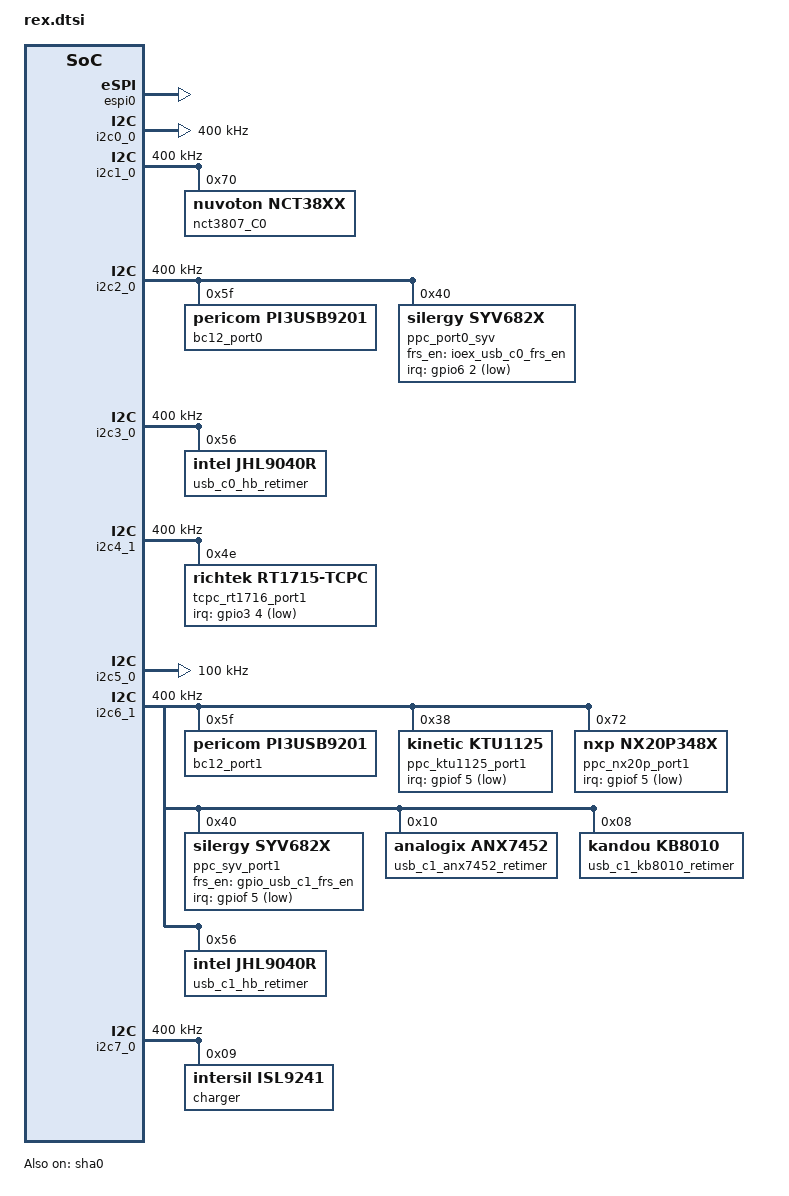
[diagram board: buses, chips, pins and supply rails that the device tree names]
/* Copyright 2022 The ChromiumOS Authors
 * Use of this source code is governed by a BSD-style license that can be
 * found in the LICENSE file.
 */

#include <dt-bindings/usb_pd_tcpm.h>
#include <cros/integrated_fwid.dtsi>

/ {
	aliases {
		gpio-wp = &gpio_ec_wp_l;
		gpio-cbi-wp = &gpio_ec_cbi_wp;
		gpio-kbd-kso2 = &gpio_ec_kso_02_inv;
	};

	named-gpios {
		compatible = "named-gpios";

		gpio_ec_entering_rw: ec_entering_rw {
			enum-name = "GPIO_ENTERING_RW";
		};

		ioex_usb_c0_sbu_fault_odl: usb_c0_sbu_fault_odl {
			gpios = <&ioex_c0_port1 2 GPIO_INPUT>;
		};
		ioex_usb_c0_rt_rst_ls_l: usb_c0_rt_rst_ls_l {
			gpios = <&ioex_c0_port0 7 GPIO_OUTPUT>;
		};

		ioex_usb_c0_frs_en: usb_c0_frs_en {
			gpios = <&ioex_c0_port0 6 GPIO_OUTPUT_LOW>;
		};

		/* Need to designate 1.8V for I2C buses on the 1800mV rail */
		ec-i2c-sensor-scl {
			gpios = <&gpiob 5 (GPIO_INPUT | GPIO_VOLTAGE_1P8)>;
		};
		ec-i2c-sensor-sda {
			gpios = <&gpiob 4 (GPIO_INPUT | GPIO_VOLTAGE_1P8)>;
		};
		ec-i2c-c0-rt-scl {
			gpios = <&gpiod 1 (GPIO_INPUT | GPIO_VOLTAGE_1P8)>;
		};
		ec-i2c-c0-rt-sda {
			gpios = <&gpiod 0 (GPIO_INPUT | GPIO_VOLTAGE_1P8)>;
		};

		/* Overrides for generated.dtsi */
		ec_edp_bl_en {
			gpios = <&gpiod 3 GPIO_OUTPUT_LOW>;
		};
		en_pp5000_fan {
			gpios = <&gpio6 1 GPIO_OUTPUT_LOW>;
		};
		usb_c0_tcpc_rst_odl {
			gpios = <&gpio6 7 (GPIO_ODR_HIGH | GPIO_ACTIVE_LOW)>;
		};
		usb_c0_ppc_int_odl {
			gpios = <&gpio6 2 (GPIO_INPUT | GPIO_ACTIVE_LOW)>;
		};
		usb_c1_ppc_int_odl {
			gpios = <&gpiof 5 (GPIO_INPUT | GPIO_ACTIVE_LOW)>;
		};
	};

	named-gpios {
		compatible = "named-gpios";

		/*
		 * Override auto-generated GPIO definitions for pins
		 * that are reconfigured at runtime for specific
		 * daughterboards.
		 *
		 * The flags parameter needs to be 0 here because
		 * gpio_pin_configure_dt() can only add flags.
		 */

		usb_c1_rst_odl {
			gpios = <&gpio3 7 0>;
			no-auto-init;
		};
		usb_c1_rt_int_odl {
			gpios = <&gpio7 2 0>;
			no-auto-init;
		};
		usb_c1_rt_rst_r_odl {
			gpios = <&gpio7 4 0>;
			no-auto-init;
		};
		usb_c1_frs_en {
			gpios = <&gpio8 3 0>;
			no-auto-init;
		};
	};

	aliases {
		/* GPIO37 */
		kb-usb-c1-rst-odl = &gpio_usb_c1_rst_odl;
		anx-usb-c1-rt-hpd-in = &gpio_usb_c1_rst_odl;
		hb-usb-c1-rst-odl = &gpio_usb_c1_rst_odl;

		/* GPIO72 */
		kb-usb-c1-dp-mode = &gpio_usb_c1_rt_int_odl;
		anx-usb-c1-rt-dp-en = &gpio_usb_c1_rt_int_odl;
		hb-usb-c1-int-odl = &gpio_usb_c1_rt_int_odl;

		/* GPIO74 */
		ps-usb-c1-rt-rst-odl = &gpio_usb_c1_rt_rst_r_odl;
		kb-usb-c1-rt-rst-odl = &gpio_usb_c1_rt_rst_r_odl;
		anx-usb-c1-rt-usb-en = &gpio_usb_c1_rt_rst_r_odl;
		hb-usb-c1-rt-rst-odl = &gpio_usb_c1_rt_rst_r_odl;

		/* GPIO83 */
		kb-usb-c1-frs-alert = &gpio_usb_c1_frs_en;
		anx-usb-c1-frs-en = &gpio_usb_c1_frs_en;
		hb-usb-c1-frs-en = &gpio_usb_c1_frs_en;
	};

	/* Special I2C port attribute */
	named-i2c-ports {
		ec_i2c_usb_c1_tcp {
			dynamic-speed;
		};
	};

	usba-port-enable-list {
		compatible = "cros-ec,usba-port-enable-pins";
		enable-pins = <&gpio_en_pp5000_usba_r>;
	};
};

/* host interface */
&espi0 {
	status = "okay";
	pinctrl-0 = <&espi_lpc_gp46_47_51_52_53_54_55_57>;
	pinctrl-names = "default";
};

&sha0 {
	status = "okay";
};

/* Power switch logic input pads */
&psl_in1_gpd2 {
	/* LID_OPEN */
	psl-in-mode = "edge";
	psl-in-pol = "high-rising";
};

&psl_in2_gp00 {
	/* ACOK_OD */
	psl-in-mode = "edge";
	psl-in-pol = "high-rising";
};

&psl_in4_gp02 {
	/* MECH_PWR_BTN_ODL */
	psl-in-mode = "edge";
	psl-in-pol = "low-falling";
};

/* Power domain device controlled by PSL (Power Switch Logic) IO pads */
&power_ctrl_psl {
	status = "okay";
	pinctrl-names = "sleep";
	pinctrl-0 = <&psl_in1_gpd2 &psl_in2_gp00 &psl_in4_gp02>;
};

&i2c0_0 {
	label = "I2C_SENSOR";
	clock-frequency = <I2C_BITRATE_FAST>;
};

&i2c1_0 {
	label = "I2C_USB_C0_TCPC";
	clock-frequency = <I2C_BITRATE_FAST>;

	nct3807_C0: nct38xx@70 {
		compatible = "nuvoton,nct38xx";
		reg = <0x70>;

		tcpc_port0: nct38xx-tcpc {
			compatible = "nuvoton,nct38xx-tcpc";
			gpio-dev = <&nct38xx_gpio_C0>;
			tcpc-flags = <(
				TCPC_FLAGS_TCPCI_REV2_0 |
				TCPC_FLAGS_TCPCI_REV2_0_NO_VSAFE0V)>;
			/* a duplicate of the <&gpio_usb_c0_tcpc_int_odl> node
			 * in "named-gpios". This is the Zephyr preferred style,
			 * the "named-gpios" node will be dealt with at a later
			 * date.
			 */
			irq-gpios = <&gpioe 0 GPIO_ACTIVE_LOW>;
			/* a duplicate of the <&gpio_usb_c0_tcpc_rst_odl> node
			 * in "named-gpios". This is the Zephyr preferred style,
			 * the "named-gpios" node will be dealt with at a later
			 * date.
			 */
			rst-gpios = <&gpio6 7
				     (GPIO_OPEN_DRAIN | GPIO_ACTIVE_LOW)>;
		};

		nct38xx_gpio_C0: nct38xx-gpio {
			#address-cells = <1>;
			#size-cells = <0>;
			compatible = "nuvoton,nct38xx-gpio";
			label = "NCT3807_C0";

			ioex_c0_port0: gpio@0 {
				compatible = "nuvoton,nct38xx-gpio-port";
				reg = <0x0>;
				label = "NCT3807_C0_GPIO0";
				gpio-controller;
				#gpio-cells = <2>;
				ngpios = <8>;
				pin_mask = <0xff>;
				pinmux_mask = <0xf7>;
			};
			ioex_c0_port1: gpio@1 {
				compatible = "nuvoton,nct38xx-gpio-port";
				reg = <0x1>;
				label = "NCT3807_C0_GPIO1";
				gpio-controller;
				#gpio-cells = <2>;
				ngpios = <8>;
				pin_mask = <0xff>;
			};
		};
	};
};

&i2c2_0 {
	label = "I2C_PPC0";
	clock-frequency = <I2C_BITRATE_FAST>;

	bc12_port0: pi3usb9201@5f {
		compatible = "pericom,pi3usb9201";
		status = "okay";
		reg = <0x5f>;
		irq = <&int_usb_c0_bc12>;
	};

	ppc_port0_syv: ppc_syv@40 {
		compatible = "silergy,syv682x";
		status = "okay";
		reg = <0x40>;
		frs_en_gpio = <&ioex_usb_c0_frs_en>;
		/* a duplicate of the <&gpio_usb_c0_ppc_int_odl> node in
		 * "named-gpios". This is the Zephyr preferred style,
		 * the "named-gpios" node will be dealt with at a later date.
		 */
		irq-gpios = <&gpio6 2 GPIO_ACTIVE_LOW>;
	};
};

&i2c3_0 {
	label = "I2C_USB_C0_RT";
	clock-frequency = <I2C_BITRATE_FAST>;

	usb_c0_hb_retimer: jhl9040r-c0@56 {
		compatible = "intel,jhl9040r";
		reg = <0x56>;
		ls-en-pin = <&gpio_usb_c0_rt_3p3_sx_en>;
		int-pin = <&gpio_usb_c0_rt_int_odl>;
		reset-pin = <&ioex_usb_c0_rt_rst_ls_l>;
	};
};

&i2c4_1 {
	label = "I2C_USB_C1_TCPC";
	clock-frequency = <I2C_BITRATE_FAST>;

	tcpc_rt1716_port1: rt1716@4e {
		compatible = "richtek,rt1715-tcpc";
		reg = <0x4e>;
		tcpc-flags = <(TCPC_FLAGS_TCPCI_REV2_0 |
			TCPC_FLAGS_TCPCI_REV2_0_NO_VSAFE0V)>;
		/* a duplicate of the <&gpio_usb_c1_tcpc_int_odl> node in
		 * "named-gpios". This is the Zephyr preferred style,
		 * the "named-gpios" node will be dealt with at a later date.
		 */
		irq-gpios = <&gpio3 4 GPIO_ACTIVE_LOW>;
		is-alt;
	};
};

&i2c5_0 {
	label = "I2C_BATTERY";
	clock-frequency = <I2C_BITRATE_STANDARD>;

	/* Upstream zephyr uses an irregular name here */
	pinctrl-0 = <&i2c5_0_sda_scl_gp33_36>;
};

&i2c6_1 {
	label = "I2C_USB_1_MIX";
	clock-frequency = <I2C_BITRATE_FAST>;

	bc12_port1: pi3usb9201@5f {
		compatible = "pericom,pi3usb9201";
		status = "okay";
		reg = <0x5f>;
		irq = <&int_usb_c1_bc12>;
	};

	ppc_ktu1125_port1: ktu1125@38 {
		compatible = "kinetic,ktu1125";
		status = "okay";
		reg = <0x38>;
		/* a duplicate of the <&gpio_usb_c1_ppc_int_odl> node in
		 * "named-gpios". This is the Zephyr preferred style,
		 * the "named-gpios" node will be dealt with at a later date.
		 */
		irq-gpios = <&gpiof 5 GPIO_ACTIVE_LOW>;
		is-alt;
	};

	ppc_nx20p_port1: nx20p348x@72 {
		compatible = "nxp,nx20p348x";
		status = "okay";
		reg = <0x72>;
		/* a duplicate of the <&gpio_usb_c1_ppc_int_odl> node in
		 * "named-gpios". This is the Zephyr preferred style,
		 * the "named-gpios" node will be dealt with at a later date.
		 */
		irq-gpios = <&gpiof 5 GPIO_ACTIVE_LOW>;
		is-alt;
	};

	ppc_syv_port1: ppc_syv@40 {
		compatible = "silergy,syv682x";
		status = "okay";
		reg = <0x40>;
		frs_en_gpio = <&gpio_usb_c1_frs_en>;
		/* a duplicate of the <&gpio_usb_c1_ppc_int_odl> node in
		 * "named-gpios". This is the Zephyr preferred style,
		 * the "named-gpios" node will be dealt with at a later date.
		 */
		irq-gpios = <&gpiof 5 GPIO_ACTIVE_LOW>;
		is-alt;
	};

	usb_c1_anx7452_retimer: usb-c1-anx7452-retimer@10 {
		compatible = "analogix,anx7452";
		reg = <0x10>;
		usb-en-pin = <&gpio_usb_c1_rt_rst_r_odl>;
		dp-en-pin = <&gpio_usb_c1_rt_int_odl>;
	};

	usb_c1_kb8010_retimer: usb-c1-kb8010-retimer@8 {
		compatible = "kandou,kb8010";
		reg = <0x08>;
		reset-pin = <&gpio_usb_c1_rt_rst_r_odl>;
		dp-en-pin = <&gpio_usb_c1_rt_int_odl>;
	};

	usb_c1_hb_retimer: usb-c1-hb-retimer@56 {
		compatible = "intel,jhl9040r";
		reg = <0x56>;
		ls-en-pin = <&gpio_usb_c1_rst_odl>;
		int-pin = <&gpio_usb_c1_rt_int_odl>;
		reset-pin = <&gpio_usb_c1_rt_rst_r_odl>;
	};

};

&i2c7_0 {
	label = "I2C_CHARGER";
	clock-frequency = <I2C_BITRATE_FAST>;

	charger: isl9241@9 {
		compatible = "intersil,isl9241";
		status = "okay";
		reg = <0x09>;
	};
};
